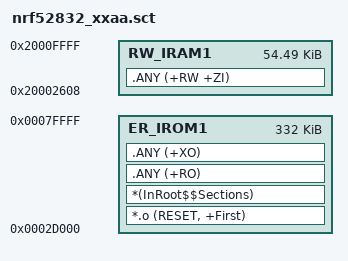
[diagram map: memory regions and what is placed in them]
; *************************************************************
; *** Scatter-Loading Description File generated by uVision ***
; *************************************************************

LR_IROM1 0x0002D000 0x00053000  {    ; load region size_region
  ER_IROM1 0x0002D000 0x00053000  {  ; load address = execution address
   *.o (RESET, +First)
   *(InRoot$$Sections)
   .ANY (+RO)
   .ANY (+XO)
  }
  RW_IRAM1 0x20002608 0x0000D9F8  {  ; RW data
   .ANY (+RW +ZI)
  }
}

